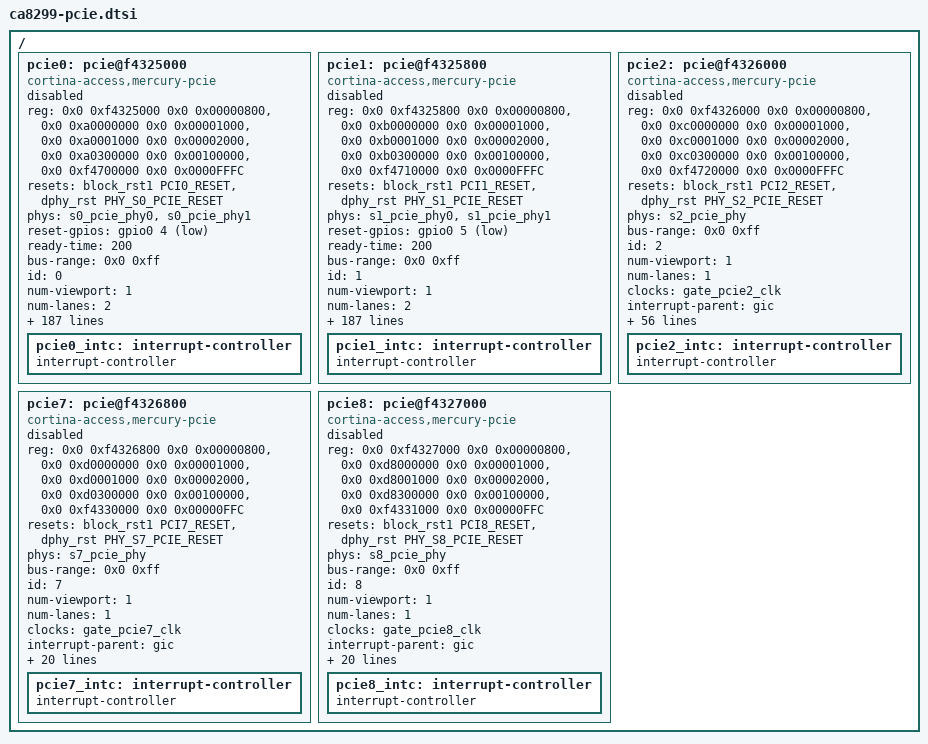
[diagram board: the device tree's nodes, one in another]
// SPDX-License-Identifier: GPL-2.0
/*
 * Copyright (C) 2024, Cortina Access Inc.
 *
 * ca8299-pcie.dtsi - Device Tree Include file for CA8299
 * pin controller.
 */
#include <dt-bindings/gpio/gpio.h>
/ {

/* Synopsis Designware PCIe interface */
	/* explained in Documentation/devicetree/bindings/pci/ca77xx-pcie.txt */
	//pcie0: pcie@f4325080 {
	pcie0: pcie@f4325000 {
		compatible = "cortina-access,mercury-pcie";
		reg = <0x0 0xf4325000 0x0 0x00000800>,
		      <0x0 0xa0000000 0x0 0x00001000>,
		      <0x0 0xa0001000 0x0 0x00002000>,
		      <0x0 0xa0300000 0x0 0x00100000>,
		      <0x0 0xf4700000 0x0 0x0000FFFC>;
		reg-names = "glbl_regs", "rc_dbi", "config", "iatu","serdes_phy";

		resets = <&block_rst1 PCI0_RESET>, <&dphy_rst PHY_S0_PCIE_RESET>;
		reset-names = "core_reset", "phy_reset";

		phys = <&s0_pcie_phy0>, <&s0_pcie_phy1>;
		phy-names = "pcie-phy0", "pcie-phy1";

		reset-gpios = <&gpio0 4 GPIO_ACTIVE_LOW>;
		ready-time = /bits/ 16 <200>;

		#address-cells = <3>;
		#size-cells = <2>;

		device_type = "pci";
		bus-range = <0x0 0xff>;
		ranges = <0x81000000 0 0          0 0xa0003000 0 0x00010000
			/* downstream I/O */
			/* 0xa0300000 - 0xa03fffff reserved for controller */
			0x82000000 0 0xa0400000 0 0xa0400000 0 0x0fc00000>;
			/* non-prefetchable memory */

		id = <0>;
		num-viewport = <1>;
		num-lanes = <2>;
		clocks = <&gate_pcie0_clk>;
		//iommus = <&pcie0_atu>;

		interrupt-parent = <&gic>;
		interrupts = <GIC_SPI IRQ_GLB_PCIE0_GIC0 IRQ_TYPE_LEVEL_HIGH>,
					/* controller interrupt */
					<GIC_SPI IRQ_GLB_PCIE0_GIC1 IRQ_TYPE_LEVEL_HIGH>,
					<GIC_SPI IRQ_GLB_PCIE0_GIC2 IRQ_TYPE_LEVEL_HIGH>,
					<GIC_SPI IRQ_GLB_PCIE0_GIC3 IRQ_TYPE_LEVEL_HIGH>;

		irq-affinity = <1>;  /*RTK wifi. Bound to CPU1. */

		status = "disabled";
		/* Serdes PHY parameters */
		serdes-cfg-verA = "revA v0.7 (2025.02.19)";
		serdes-cfg-dataA =
					<0x70B8 0x08f0>,
					<0x8180 0x40c1>,
					<0x9180 0x40c1>,
					<0xA180 0x40c1>,
					<0xB180 0x40c1>,
					<0x8580 0x40c1>,
					<0x9580 0x40c1>,
					<0xA580 0x40c1>,
					<0xB580 0x40c1>,
					<0x80C0 0xffd0>,
					<0x90C0 0xffd0>,
					<0xA0C0 0xffd0>,
					<0xB0C0 0xffd0>,
					<0x84C0 0xffd0>,
					<0x94C0 0xffd0>,
					<0xA4C0 0xffd0>,
					<0xB4C0 0xffd0>,
					<0x8090 0x0100>,
					<0x9090 0x0100>,
					<0xA090 0x0100>,
					<0xB090 0x0100>,
					<0x8490 0x0100>,
					<0x9490 0x0100>,
					<0xA490 0x0100>,
					<0xB490 0x0100>,
					<0x011C 0x2>,
					<0x051C 0x2>,
					<0x091C 0x2>,
					<0x0D1C 0x2>,
					<0x01DC 0x2>,
					<0x05DC 0x2>,
					<0x09DC 0x2>,
					<0x0DDC 0x2>,
					<0x0124 0x4001>,
					<0x0524 0x4001>,
					<0x0924 0x4001>,
					<0x0D24 0x4001>,
					<0x01E4 0x4001>,
					<0x05E4 0x4001>,
					<0x09E4 0x4001>,
					<0x0DE4 0x4001>,
					<0x012C 0x38>,
					<0x052C 0x38>,
					<0x092C 0x38>,
					<0x0D2C 0x38>,
					<0x01EC 0x38>,
					<0x05EC 0x38>,
					<0x09EC 0x38>,
					<0x0DEC 0x38>,
					<0x8028 0x3000>,
					<0x9028 0x2000>,
					<0xA028 0x2000>,
					<0xB028 0x2000>,
					<0x8428 0x3000>,
					<0x9428 0x2000>,
					<0xA428 0x2000>,
					<0xB428 0x2000>,
					<0x8130 0xFECF>,
					<0x9130 0xFECF>,
					<0xA130 0xFECF>,
					<0xB130 0xFECF>,
					<0x8530 0xFECF>,
					<0x9530 0xFECF>,
					<0xA530 0xFECF>,
					<0xB530 0xFECF>,
					<0x80D0 0xaff0>,
					<0x90D0 0xaff0>,
					<0xA0D0 0xaff0>,
					<0xB0D0 0x9840>,
					<0x84D0 0xaff0>,
					<0x94D0 0xaff0>,
					<0xA4D0 0xaff0>,
					<0xB4D0 0x9840>,
					<0x8150 0x79e>,
					<0x9150 0x79e>,
					<0xA150 0x79e>,
					<0xB150 0x79e>,
					<0x8550 0x79e>,
					<0x9550 0x79e>,
					<0xA550 0x79e>,
					<0xB550 0x79e>,
					<0x81C8 0x8038>,
					<0x91C8 0x8038>,
					<0xA1C8 0x8038>,
					<0xB1C8 0x8038>,
					<0x85C8 0x8038>,
					<0x95C8 0x8038>,
					<0xA5C8 0x8038>,
					<0xB5C8 0x8038>,
					<0x80A8 0x3f20>,
					<0x90A8 0x3f20>,
					<0xA0A8 0x3f20>,
					<0xB0A8 0x3f20>,
					<0x84A8 0x3f20>,
					<0x94A8 0x3f20>,
					<0xA4A8 0x3f20>,
					<0xB4A8 0x3f20>,
					<0x8248 0x6002>,
					<0x9248 0x6002>,
					<0xA248 0x2002>,
					<0xB248 0x2002>,
					<0x8648 0x6002>,
					<0x9648 0x6002>,
					<0xA648 0x2002>,
					<0xB648 0x2002>,
					<0x8250 0x8008>,
					<0x9250 0x8008>,
					<0xA250 0x8008>,
					<0xB250 0x8008>,
					<0x8650 0x8008>,
					<0x9650 0x8008>,
					<0xA650 0x8008>,
					<0xB650 0x8008>,
					<0x8268 0xc49>,
					<0x9268 0xc49>,
					<0xA268 0xe49>,
					<0xB268 0xe49>,
					<0x8668 0xc49>,
					<0x9668 0xc49>,
					<0xA668 0xe49>,
					<0xB668 0xe49>,
					<0x8110 0x7800>,
					<0x9110 0x7800>,
					<0xA110 0x7800>,
					<0xB110 0x7800>,
					<0x8510 0x7800>,
					<0x9510 0x7800>,
					<0xA510 0x7800>,
					<0xB510 0x7800>,
					<0x8118 0x7800>,
					<0x9118 0x7800>,
					<0xA118 0x7800>,
					<0xB118 0x7800>,
					<0x8518 0x7800>,
					<0x9518 0x7800>,
					<0xA518 0x7800>,
					<0xB518 0x7800>,
					<0x8120 0x320>,
					<0x9120 0x320>,
					<0xA120 0x320>,
					<0xB120 0x320>,
					<0x8520 0x320>,
					<0x9520 0x320>,
					<0xA520 0x320>,
					<0xB520 0x320>,
					<0x8128 0x320>,
					<0x9128 0x320>,
					<0xA128 0x320>,
					<0xB128 0x320>,
					<0x8528 0x320>,
					<0x9528 0x320>,
					<0xA528 0x320>,
					<0xB528 0x320>,
					<0x8148 0x80A6>,
					<0x9148 0x80A6>,
					<0xA148 0x80A6>,
					<0xB148 0x80A6>,
					<0x8548 0x80A6>,
					<0x9548 0x80A6>,
					<0xA548 0x80A6>,
					<0xB548 0x80A6>,
					<0x8140 0x0000>,
					<0x9140 0x0000>,
					<0xA140 0x0000>,
					<0xB140 0x3980>,
					<0x8540 0x0000>,
					<0x9540 0x0000>,
					<0xA540 0x0000>,
					<0xB540 0x3980>,
					<0x8178 0x0000>,
					<0x9178 0x0000>,
					<0xA178 0x0000>,
					<0xB178 0x0000>,
					<0x8578 0x0000>,
					<0x9578 0x0000>,
					<0xA578 0x0000>,
					<0xB578 0x0000>,
					<0x8108 0x0010>,
					<0x9108 0x0010>,
					<0xA108 0x0010>,
					<0xB108 0x0010>,
					<0x8508 0x0010>,
					<0x9508 0x0010>,
					<0xA508 0x0010>,
					<0xB508 0x0010>,
					<0x8160 0x2>,
					<0x9160 0x2>,
					<0xA160 0x2>,
					<0xB160 0x2>,
					<0x8560 0x2>,
					<0x9560 0x2>,
					<0xA560 0x2>,
					<0xB560 0x2>,
					<0x8168 0x0>,
					<0x9168 0x0>,
					<0xA168 0x0>,
					<0xB168 0x0>,
					<0x8568 0x0>,
					<0x9568 0x0>,
					<0xA568 0x0>,
					<0xB568 0x0>,
					<0x81E0 0x00ff>,
					<0x91E0 0x00ff>,
					<0xA1E0 0x00ff>,
					<0xB1E0 0x00ff>,
					<0x85E0 0x00ff>,
					<0x95E0 0x00ff>,
					<0xA5E0 0x00ff>,
					<0xB5E0 0x00ff>,
					<0x81F0 0x00ff>,
					<0x91F0 0x00ff>,
					<0xA1F0 0x00ff>,
					<0xB1F0 0x00ff>,
					<0x85F0 0x00ff>,
					<0x95F0 0x00ff>,
					<0xA5F0 0x00ff>,
					<0xB5F0 0x00ff>,
					<0x8260 0x2000>,
					<0x9260 0x2000>,
					<0xA260 0x2000>,
					<0xB260 0x2000>,
					<0x8660 0x2000>,
					<0x9660 0x2000>,
					<0xA660 0x2000>,
					<0xB660 0x2000>,
					<0x8220 0x64>,
					<0x9220 0x64>,
					<0xA220 0x64>,
					<0xB220 0x64>,
					<0x8620 0x64>,
					<0x9620 0x64>,
					<0xA620 0x64>,
					<0xB620 0x64>,
					<0x8230 0x2700>,
					<0x9230 0x2700>,
					<0xA230 0x3E70>,
					<0xB230 0x3E70>,
					<0x8630 0x2700>,
					<0x9630 0x2700>,
					<0xA630 0x3E70>,
					<0xB630 0x3E70>,
					<0x8228 0x2700>,
					<0x9228 0x2700>,
					<0xA228 0x3E70>,
					<0xB228 0x3E70>,
					<0x8628 0x2700>,
					<0x9628 0x2700>,
					<0xA628 0x3E70>,
					<0xB628 0x3E70>,
					<0xC000 0x0fff>,
					<0xD000 0x0fff>,
					<0xE000 0x0fff>,
					<0xF000 0x0fff>,
					<0x8270 0x6780>,
					<0x9270 0x6780>,
					<0xA270 0x6780>,
					<0xB270 0x6780>,
					<0x8670 0x6780>,
					<0x9670 0x6780>,
					<0xA670 0x6780>,
					<0xB670 0x6780>,
					<0x81B8 0x6000>,
					<0x91B8 0x6000>,
					<0xA1B8 0x6000>,
					<0xB1B8 0x6000>,
					<0x85B8 0x6000>,
					<0x95B8 0x6000>,
					<0xA5B8 0x6000>,
					<0xB5B8 0x6000>,
					<0x0058 0xc970>,
					<0x0458 0xc970>,
					<0x0858 0xc970>,
					<0x0C58 0xc970>,
					<0x0044 0xc10d>,
					<0x0444 0xc10d>,
					<0x0844 0xc10d>,
					<0x0C44 0xc10c>,
					<0x0068 0xd2f0>,
					<0x0468 0xd2f0>,
					<0x0868 0x52f0>,
					<0x0C68 0x52f0>,
					<0x00C8 0x5c0f>,
					<0x04C8 0x6c0f>,
					<0x08C8 0x7c0f>,
					<0x0CC8 0x7c0f>,
					<0x0188 0x5c0f>,
					<0x0588 0x6c0f>,
					<0x0988 0x7c0f>,
					<0x0D88 0x7c0f>,
					<0x00DC 0x0240>,
					<0x04DC 0x0240>,
					<0x08DC 0x0240>,
					<0x0CDC 0x0240>,
					<0x019C 0x0240>,
					<0x059C 0x0240>,
					<0x099C 0x0240>,
					<0x0D9C 0x0240>,
					<0x00C0 0x0600>,
					<0x04C0 0x0600>,
					<0x08C0 0x0e00>,
					<0x0CC0 0x0e00>,
					<0x0180 0x0600>,
					<0x0580 0x0600>,
					<0x0980 0x0e00>,
					<0x0D80 0x0e00>,
					<0xC118 0x2b>,
					<0xD118 0x2b>,
					<0xE118 0x2b>,
					<0xF118 0x2b>,
					<0x7218 0xf104>,
					<0x7258 0xf145>,
					<0x7260 0xe1c7>,
					<0x7280 0x9880>,
					<0x72C0 0xd880>,
					<0x016C 0x8044>,
					<0x056C 0x8044>,
					<0x096C 0x8044>,
					<0x0D6C 0x804c>,
					<0x022C 0x8044>,
					<0x062C 0x8044>,
					<0x0A2C 0x8044>,
					<0x0E2C 0x804c>,
					<0x0174 0x8e7c>,
					<0x0574 0x8e7c>,
					<0x0974 0x8e7c>,
					<0x0D74 0x8e7c>,
					<0x0234 0x8e7c>,
					<0x0634 0x8e7c>,
					<0x0A34 0x8e7c>,
					<0x0E34 0x8e7c>,
					<0x015C 0x8000>,
					<0x055C 0x8000>,
					<0x095C 0x1000>,
					<0x0D5C 0x1000>,
					<0x021C 0x8000>,
					<0x061C 0x8000>,
					<0x0A1C 0x1000>,
					<0x0E1C 0x1000>,
					<0x0104 0x1e4>,
					<0x0504 0x1e4>,
					<0x0904 0x0a4>,
					<0x0D04 0x0a4>,
					<0x01C4 0x1e4>,
					<0x05C4 0x1e4>,
					<0x09C4 0x0a4>,
					<0x0DC4 0x0a4>,
					<0x0138 0x0744>,
					<0x0538 0x0044>,
					<0x0938 0x0043>,
					<0x0D38 0x0043>,
					<0x01F8 0x0744>,
					<0x05F8 0x0044>,
					<0x09F8 0x0043>,
					<0x0DF8 0x0043>,
					<0x0170 0x8864>,
					<0x0570 0x8864>,
					<0x0970 0x8864>,
					<0x0D70 0x8864>,
					<0x0230 0x8864>,
					<0x0630 0x8864>,
					<0x0A30 0x8864>,
					<0x0E30 0x8864>,
					<0x0164 0x5680>,
					<0x0564 0x5680>,
					<0x0964 0x5a82>,
					<0x0D64 0x5a82>,
					<0x0224 0x5680>,
					<0x0624 0x5680>,
					<0x0A24 0x5a82>,
					<0x0E24 0x5a82>,
					<0x80B0 0x000d>,
					<0x90B0 0x000d>,
					<0xA0B0 0x000d>,
					<0xB0B0 0x000d>,
					<0x84B0 0x000d>,
					<0x94B0 0x000d>,
					<0xA4B0 0x000d>,
					<0xB4B0 0x000d>,
					<0x8258 0x1ff>,
					<0x9258 0x1ff>,
					<0xA258 0x1ff>,
					<0xB258 0x1ff>,
					<0x8658 0x1ff>,
					<0x9658 0x1ff>,
					<0xA658 0x1ff>,
					<0xB658 0x1ff>,
					<0x8210 0x3>,
					<0x9210 0x3>,
					<0xA210 0x3>,
					<0xB210 0x3>,
					<0x8610 0x3>,
					<0x9610 0x3>,
					<0xA610 0x3>,
					<0xB610 0x3>,
					<0x0108 0x17>,
					<0x0508 0x16>,
					<0x0908 0x14>,
					<0x0D08 0x10>,
					<0x01C8 0x17>,
					<0x05C8 0x16>,
					<0x09C8 0x14>,
					<0x0DC8 0x10>,
					<0x80A0 0x11e0>,
					<0x90A0 0x11e0>,
					<0xA0A0 0x11e0>,
					<0xB0A0 0x11e0>,
					<0x84A0 0x11e0>,
					<0x94A0 0x11e0>,
					<0xA4A0 0x11e0>,
					<0xB4A0 0x11e0>,
					<0x8030 0x200>,
					<0x9030 0x200>,
					<0xA030 0x200>,
					<0xB030 0x200>,
					<0x8430 0x200>,
					<0x9430 0x200>,
					<0xA430 0x200>,
					<0xB430 0x200>,
					<0x0100 0x67c3>,
					<0x0500 0x67c3>,
					<0x0900 0x67c3>,
					<0x0D00 0x66c3>,
					<0x01C0 0x67c3>,
					<0x05C0 0x67c3>,
					<0x09C0 0x67c3>,
					<0x0DC0 0x66c3>,
					<0x0144 0xe0c>,
					<0x0544 0xe0c>,
					<0x0944 0x60c>,
					<0x0D44 0x40c>,
					<0x0204 0xe0c>,
					<0x0604 0xe0c>,
					<0x0A04 0x60c>,
					<0x0E04 0x40c>,
					<0x0148 0xa63>,
					<0x0548 0xa63>,
					<0x0948 0xa63>,
					<0x0D48 0xa63>,
					<0x0208 0xa63>,
					<0x0608 0xa63>,
					<0x0A08 0xa63>,
					<0x0E08 0xa63>,
					<0x0168 0x101A>,
					<0x0568 0x101A>,
					<0x0968 0x101A>,
					<0x0D68 0x101A>,
					<0x0228 0x101A>,
					<0x0628 0x101A>,
					<0x0A28 0x101A>,
					<0x0E28 0x101A>,
					<0x0158 0x4200>,
					<0x0558 0x4200>,
					<0x0958 0x4200>,
					<0x0D58 0x4200>,
					<0x0218 0x4200>,
					<0x0618 0x4200>,
					<0x0A18 0x4200>,
					<0x0E18 0x4200>,
					<0x81D0 0xffff>,
					<0x91D0 0xffff>,
					<0xA1D0 0xffff>,
					<0xB1D0 0xffff>,
					<0x85D0 0xffff>,
					<0x95D0 0xffff>,
					<0xA5D0 0xffff>,
					<0xB5D0 0xffff>,
					<0x8098 0x108>,
					<0x9098 0x108>,
					<0xA098 0x108>,
					<0xB098 0x108>,
					<0x8498 0x108>,
					<0x9498 0x108>,
					<0xA498 0x108>,
					<0xB498 0x108>,
					<0x8068 0x426c>,
					<0x9068 0x426c>,
					<0xA068 0x426c>,
					<0xB068 0xc26c>,
					<0x8468 0x426c>,
					<0x9468 0x426c>,
					<0xA468 0x426c>,
					<0xB468 0xc26c>,
					<0x8008 0x0000>,
					<0x9008 0x0000>,
					<0xA008 0x0000>,
					<0xB008 0x60>,
					<0x8408 0x0000>,
					<0x9408 0x0000>,
					<0xA408 0x0000>,
					<0xB408 0x60>;

		mac_pset_fs = <42>;
		mac_pset_lf = <14>;
		mac_preset_cfg = /*p0 - p10, Pre, Main, Post*/
					<0 31 11>,
					<0 35 7>,
					<0 34 8>,
					<0 37 5>,
					<0 42 0>,
					<4 38 0>,
					<5 37 0>,
					<4 30 8>,
					<5 32 5>,
					<7 35 0>,
					<0 28 14>;

		ephy_cnt = <3>;
		ephy_addr = /bits/ 16
						<0x1c62 0x1c60 0x1c60>;

		tx_data_size = <147>;
		tx_matrix_data = /bits/ 16
					<0x0 0x3C0 0x0
					0x821 0x3C1 0x1
					0x1042 0x3C2 0x2
					0x1863 0x3C3 0x3
					0x2084 0x3C4 0x4
					0x28A6 0x3C5 0x5
					0x30C7 0x3C6 0x6
					0x40E8 0x3C7 0x7
					0x4909 0x3C8 0x8
					0x5129 0x3C9 0x9
					0x5949 0x3CA 0xA
					0x6169 0x3CB 0xB
					0x6989 0x3CC 0xC
					0x71A9 0x3CD 0xD
					0x71C9 0x3CE 0xE
					0x79E9 0x3CF 0xF
					0x7A09 0x3D0 0x10
					0x7A49 0x3D1 0x11
					0x7A69 0x3D2 0x12
					0x7A89 0x3D3 0x13
					0x7AA9 0x3D4 0x14
					0x7AE9 0x3D5 0x15
					0x7B09 0x3D6 0x16
					0x7B29 0x3D7 0x17
					0x7B69 0x3D8 0x18
					0x7B89 0x3D9 0x19
					0x7BC9 0x3DA 0x1A
					0x7C09 0x3DB 0x1B
					0x7C49 0x3DC 0x1C
					0x7C89 0x3DD 0x1D
					0x7CC9 0x3DE 0x1E
					0x7D09 0x3DF 0x1F
					0x7D69 0x3E0 0x20
					0x7DC9 0x3E1 0x21
					0x7E29 0x3E2 0x22
					0x7EA9 0x3E3 0x23
					0x7F69 0x3E4 0x24
					0x7FE9 0x3E5 0x25
					0x7FE9 0x3E6 0x26
					0x7FE9 0x3E7 0x27
					0x7FE9 0x3E8 0x28
					0x7FE9 0x3E9 0x29
					0x7FE9 0x3EA 0x2A
					0x7FE9 0x3EB 0x2B
					0x7FE9 0x3EC 0x2C
					0x7FE9 0x3ED 0x2D
					0x7FE9 0x3EE 0x2E
					0x7FE9 0x3EF 0x2F
					0x7FE9 0x3F0 0x30>;

		#interrupt-cells = <1>;
		interrupt-map-mask = <0 0 0 7>;
//		interrupt-map-mask = <0xffffffff 0x0>;
		interrupt-map = <0 0 0 1 &pcie0_intc 1>, /* INT A */
				<0 0 0 2 &pcie0_intc 2>, /* INT B */
				<0 0 0 3 &pcie0_intc 3>, /* INT C */
				<0 0 0 4 &pcie0_intc 4>; /* INT D */
		pcie0_intc: interrupt-controller {
			interrupt-controller;
			#address-cells = <0>;
			#interrupt-cells = <1>;
		};
	};
	pcie1: pcie@f4325800 {
		compatible = "cortina-access,mercury-pcie";
		reg = <0x0 0xf4325800 0x0 0x00000800>,
		      <0x0 0xb0000000 0x0 0x00001000>,
		      <0x0 0xb0001000 0x0 0x00002000>,
		      <0x0 0xb0300000 0x0 0x00100000>,
		      <0x0 0xf4710000 0x0 0x0000FFFC>;
		reg-names = "glbl_regs", "rc_dbi", "config", "iatu","serdes_phy";

		resets = <&block_rst1 PCI1_RESET>, <&dphy_rst PHY_S1_PCIE_RESET>;
		reset-names = "core_reset", "phy_reset";

		phys = <&s1_pcie_phy0>, <&s1_pcie_phy1>;
		phy-names = "pcie-phy0", "pcie-phy1";

		reset-gpios = <&gpio0 5 GPIO_ACTIVE_LOW>;
		ready-time = /bits/ 16 <200>;

		#address-cells = <3>;
		#size-cells = <2>;

		device_type = "pci";
		bus-range = <0x0 0xff>;
		ranges = <0x81000000 0 0          0 0xb0003000 0 0x00010000
			/* downstream I/O */
			/* 0xb0300000 - 0xb03fffff reserved for controller */
			0x82000000 0 0xb0400000 0 0xb0400000 0 0x0fc00000>;
			/* non-prefetchable memory */

		id = <1>;
		num-viewport = <1>;
		num-lanes = <2>;
		clocks = <&gate_pcie1_clk>;
		//iommus = <&pcie1_atu>;

		interrupt-parent = <&gic>;
		interrupts = <GIC_SPI IRQ_GLB_PCIE1_GIC0 IRQ_TYPE_LEVEL_HIGH>,
					/* controller interrupt */
					<GIC_SPI IRQ_GLB_PCIE1_GIC1 IRQ_TYPE_LEVEL_HIGH>,
					<GIC_SPI IRQ_GLB_PCIE1_GIC2 IRQ_TYPE_LEVEL_HIGH>,
					<GIC_SPI IRQ_GLB_PCIE1_GIC3 IRQ_TYPE_LEVEL_HIGH>;

		irq-affinity = <1>;  /*RTK wifi. Bound to CPU1. */

		status = "disabled";
		/* Serdes PHY parameters */
		serdes-cfg-verA = "revA v0.7 (2025.02.19)";
		serdes-cfg-dataA =
					<0x70B8 0x08f0>,
					<0x8180 0x40c1>,
					<0x9180 0x40c1>,
					<0xA180 0x40c1>,
					<0xB180 0x40c1>,
					<0x8580 0x40c1>,
					<0x9580 0x40c1>,
					<0xA580 0x40c1>,
					<0xB580 0x40c1>,
					<0x80C0 0xffd0>,
					<0x90C0 0xffd0>,
					<0xA0C0 0xffd0>,
					<0xB0C0 0xffd0>,
					<0x84C0 0xffd0>,
					<0x94C0 0xffd0>,
					<0xA4C0 0xffd0>,
					<0xB4C0 0xffd0>,
					<0x8090 0x0100>,
					<0x9090 0x0100>,
					<0xA090 0x0100>,
					<0xB090 0x0100>,
					<0x8490 0x0100>,
					<0x9490 0x0100>,
					<0xA490 0x0100>,
					<0xB490 0x0100>,
					<0x011C 0x2>,
					<0x051C 0x2>,
					<0x091C 0x2>,
					<0x0D1C 0x2>,
					<0x01DC 0x2>,
					<0x05DC 0x2>,
					<0x09DC 0x2>,
					<0x0DDC 0x2>,
					<0x0124 0x4001>,
					<0x0524 0x4001>,
					<0x0924 0x4001>,
					<0x0D24 0x4001>,
					<0x01E4 0x4001>,
					<0x05E4 0x4001>,
					<0x09E4 0x4001>,
					<0x0DE4 0x4001>,
					<0x012C 0x38>,
					<0x052C 0x38>,
					<0x092C 0x38>,
					<0x0D2C 0x38>,
					<0x01EC 0x38>,
					<0x05EC 0x38>,
					<0x09EC 0x38>,
					<0x0DEC 0x38>,
					<0x8028 0x3000>,
					<0x9028 0x2000>,
					<0xA028 0x2000>,
					<0xB028 0x2000>,
					<0x8428 0x3000>,
					<0x9428 0x2000>,
					<0xA428 0x2000>,
					<0xB428 0x2000>,
					<0x8130 0xFECF>,
					<0x9130 0xFECF>,
					<0xA130 0xFECF>,
					<0xB130 0xFECF>,
					<0x8530 0xFECF>,
					<0x9530 0xFECF>,
					<0xA530 0xFECF>,
					<0xB530 0xFECF>,
					<0x80D0 0xaff0>,
					<0x90D0 0xaff0>,
					<0xA0D0 0xaff0>,
					<0xB0D0 0x9840>,
					<0x84D0 0xaff0>,
					<0x94D0 0xaff0>,
					<0xA4D0 0xaff0>,
					<0xB4D0 0x9840>,
					<0x8150 0x79e>,
					<0x9150 0x79e>,
					<0xA150 0x79e>,
					<0xB150 0x79e>,
					<0x8550 0x79e>,
					<0x9550 0x79e>,
					<0xA550 0x79e>,
					<0xB550 0x79e>,
					<0x81C8 0x8038>,
					<0x91C8 0x8038>,
					<0xA1C8 0x8038>,
					<0xB1C8 0x8038>,
					<0x85C8 0x8038>,
					<0x95C8 0x8038>,
					<0xA5C8 0x8038>,
					<0xB5C8 0x8038>,
					<0x80A8 0x3f20>,
					<0x90A8 0x3f20>,
					<0xA0A8 0x3f20>,
					<0xB0A8 0x3f20>,
					<0x84A8 0x3f20>,
					<0x94A8 0x3f20>,
					<0xA4A8 0x3f20>,
					<0xB4A8 0x3f20>,
					<0x8248 0x6002>,
					<0x9248 0x6002>,
					<0xA248 0x2002>,
					<0xB248 0x2002>,
					<0x8648 0x6002>,
					<0x9648 0x6002>,
					<0xA648 0x2002>,
					<0xB648 0x2002>,
					<0x8250 0x8008>,
					<0x9250 0x8008>,
					<0xA250 0x8008>,
					<0xB250 0x8008>,
					<0x8650 0x8008>,
					<0x9650 0x8008>,
					<0xA650 0x8008>,
					<0xB650 0x8008>,
					<0x8268 0xc49>,
					<0x9268 0xc49>,
					<0xA268 0xe49>,
					<0xB268 0xe49>,
					<0x8668 0xc49>,
					<0x9668 0xc49>,
					<0xA668 0xe49>,
					<0xB668 0xe49>,
					<0x8110 0x7800>,
					<0x9110 0x7800>,
					<0xA110 0x7800>,
					<0xB110 0x7800>,
					<0x8510 0x7800>,
					<0x9510 0x7800>,
					<0xA510 0x7800>,
					<0xB510 0x7800>,
					<0x8118 0x7800>,
					<0x9118 0x7800>,
					<0xA118 0x7800>,
					<0xB118 0x7800>,
					<0x8518 0x7800>,
					<0x9518 0x7800>,
					<0xA518 0x7800>,
					<0xB518 0x7800>,
					<0x8120 0x320>,
					<0x9120 0x320>,
					<0xA120 0x320>,
					<0xB120 0x320>,
					<0x8520 0x320>,
					<0x9520 0x320>,
					<0xA520 0x320>,
					<0xB520 0x320>,
					<0x8128 0x320>,
					<0x9128 0x320>,
					<0xA128 0x320>,
					<0xB128 0x320>,
					<0x8528 0x320>,
					<0x9528 0x320>,
					<0xA528 0x320>,
					<0xB528 0x320>,
					<0x8148 0x80A6>,
					<0x9148 0x80A6>,
					<0xA148 0x80A6>,
					<0xB148 0x80A6>,
					<0x8548 0x80A6>,
					<0x9548 0x80A6>,
					<0xA548 0x80A6>,
					<0xB548 0x80A6>,
					<0x8140 0x0000>,
					<0x9140 0x0000>,
					<0xA140 0x0000>,
					<0xB140 0x3980>,
					<0x8540 0x0000>,
					<0x9540 0x0000>,
					<0xA540 0x0000>,
					<0xB540 0x3980>,
					<0x8178 0x0000>,
					<0x9178 0x0000>,
					<0xA178 0x0000>,
					<0xB178 0x0000>,
					<0x8578 0x0000>,
					<0x9578 0x0000>,
					<0xA578 0x0000>,
					<0xB578 0x0000>,
					<0x8108 0x0010>,
					<0x9108 0x0010>,
					<0xA108 0x0010>,
					<0xB108 0x0010>,
					<0x8508 0x0010>,
					<0x9508 0x0010>,
					<0xA508 0x0010>,
					<0xB508 0x0010>,
					<0x8160 0x2>,
					<0x9160 0x2>,
					<0xA160 0x2>,
					<0xB160 0x2>,
					<0x8560 0x2>,
					<0x9560 0x2>,
					<0xA560 0x2>,
					<0xB560 0x2>,
					<0x8168 0x0>,
					<0x9168 0x0>,
					<0xA168 0x0>,
					<0xB168 0x0>,
					<0x8568 0x0>,
					<0x9568 0x0>,
					<0xA568 0x0>,
					<0xB568 0x0>,
					<0x81E0 0x00ff>,
					<0x91E0 0x00ff>,
					<0xA1E0 0x00ff>,
					<0xB1E0 0x00ff>,
					<0x85E0 0x00ff>,
					<0x95E0 0x00ff>,
					<0xA5E0 0x00ff>,
					<0xB5E0 0x00ff>,
					<0x81F0 0x00ff>,
					<0x91F0 0x00ff>,
					<0xA1F0 0x00ff>,
					<0xB1F0 0x00ff>,
					<0x85F0 0x00ff>,
					<0x95F0 0x00ff>,
					<0xA5F0 0x00ff>,
					<0xB5F0 0x00ff>,
					<0x8260 0x2000>,
					<0x9260 0x2000>,
					<0xA260 0x2000>,
					<0xB260 0x2000>,
					<0x8660 0x2000>,
					<0x9660 0x2000>,
					<0xA660 0x2000>,
					<0xB660 0x2000>,
					<0x8220 0x64>,
					<0x9220 0x64>,
					<0xA220 0x64>,
					<0xB220 0x64>,
					<0x8620 0x64>,
					<0x9620 0x64>,
					<0xA620 0x64>,
					<0xB620 0x64>,
					<0x8230 0x2700>,
					<0x9230 0x2700>,
					<0xA230 0x3E70>,
					<0xB230 0x3E70>,
					<0x8630 0x2700>,
					<0x9630 0x2700>,
					<0xA630 0x3E70>,
					<0xB630 0x3E70>,
					<0x8228 0x2700>,
					<0x9228 0x2700>,
					<0xA228 0x3E70>,
					<0xB228 0x3E70>,
					<0x8628 0x2700>,
					<0x9628 0x2700>,
					<0xA628 0x3E70>,
					<0xB628 0x3E70>,
					<0xC000 0x0fff>,
					<0xD000 0x0fff>,
					<0xE000 0x0fff>,
					<0xF000 0x0fff>,
					<0x8270 0x6780>,
					<0x9270 0x6780>,
					<0xA270 0x6780>,
					<0xB270 0x6780>,
					<0x8670 0x6780>,
					<0x9670 0x6780>,
					<0xA670 0x6780>,
					<0xB670 0x6780>,
					<0x81B8 0x6000>,
					<0x91B8 0x6000>,
					<0xA1B8 0x6000>,
					<0xB1B8 0x6000>,
					<0x85B8 0x6000>,
					<0x95B8 0x6000>,
					<0xA5B8 0x6000>,
					<0xB5B8 0x6000>,
					<0x0058 0xc970>,
					<0x0458 0xc970>,
					<0x0858 0xc970>,
					<0x0C58 0xc970>,
					<0x0044 0xc10d>,
					<0x0444 0xc10d>,
					<0x0844 0xc10d>,
					<0x0C44 0xc10c>,
					<0x0068 0xd2f0>,
					<0x0468 0xd2f0>,
					<0x0868 0x52f0>,
					<0x0C68 0x52f0>,
					<0x00C8 0x5c0f>,
					<0x04C8 0x6c0f>,
					<0x08C8 0x7c0f>,
					<0x0CC8 0x7c0f>,
					<0x0188 0x5c0f>,
					<0x0588 0x6c0f>,
					<0x0988 0x7c0f>,
					<0x0D88 0x7c0f>,
					<0x00DC 0x0240>,
					<0x04DC 0x0240>,
					<0x08DC 0x0240>,
					<0x0CDC 0x0240>,
					<0x019C 0x0240>,
					<0x059C 0x0240>,
					<0x099C 0x0240>,
					<0x0D9C 0x0240>,
					<0x00C0 0x0600>,
					<0x04C0 0x0600>,
					<0x08C0 0x0e00>,
					<0x0CC0 0x0e00>,
					<0x0180 0x0600>,
					<0x0580 0x0600>,
					<0x0980 0x0e00>,
					<0x0D80 0x0e00>,
					<0xC118 0x2b>,
					<0xD118 0x2b>,
					<0xE118 0x2b>,
					<0xF118 0x2b>,
					<0x7218 0xf104>,
					<0x7258 0xf145>,
					<0x7260 0xe1c7>,
					<0x7280 0x9880>,
					<0x72C0 0xd880>,
					<0x016C 0x8044>,
					<0x056C 0x8044>,
					<0x096C 0x8044>,
					<0x0D6C 0x804c>,
					<0x022C 0x8044>,
					<0x062C 0x8044>,
					<0x0A2C 0x8044>,
					<0x0E2C 0x804c>,
					<0x0174 0x8e7c>,
					<0x0574 0x8e7c>,
					<0x0974 0x8e7c>,
					<0x0D74 0x8e7c>,
					<0x0234 0x8e7c>,
					<0x0634 0x8e7c>,
					<0x0A34 0x8e7c>,
					<0x0E34 0x8e7c>,
					<0x015C 0x8000>,
					<0x055C 0x8000>,
					<0x095C 0x1000>,
					<0x0D5C 0x1000>,
					<0x021C 0x8000>,
					<0x061C 0x8000>,
					<0x0A1C 0x1000>,
					<0x0E1C 0x1000>,
					<0x0104 0x1e4>,
					<0x0504 0x1e4>,
					<0x0904 0x0a4>,
					<0x0D04 0x0a4>,
					<0x01C4 0x1e4>,
					<0x05C4 0x1e4>,
					<0x09C4 0x0a4>,
					<0x0DC4 0x0a4>,
					<0x0138 0x0744>,
					<0x0538 0x0044>,
					<0x0938 0x0043>,
					<0x0D38 0x0043>,
					<0x01F8 0x0744>,
					<0x05F8 0x0044>,
					<0x09F8 0x0043>,
					<0x0DF8 0x0043>,
					<0x0170 0x8864>,
					<0x0570 0x8864>,
					<0x0970 0x8864>,
					<0x0D70 0x8864>,
					<0x0230 0x8864>,
					<0x0630 0x8864>,
					<0x0A30 0x8864>,
					<0x0E30 0x8864>,
					<0x0164 0x5680>,
					<0x0564 0x5680>,
					<0x0964 0x5a82>,
					<0x0D64 0x5a82>,
					<0x0224 0x5680>,
					<0x0624 0x5680>,
					<0x0A24 0x5a82>,
					<0x0E24 0x5a82>,
					<0x80B0 0x000d>,
					<0x90B0 0x000d>,
					<0xA0B0 0x000d>,
					<0xB0B0 0x000d>,
					<0x84B0 0x000d>,
					<0x94B0 0x000d>,
					<0xA4B0 0x000d>,
					<0xB4B0 0x000d>,
					<0x8258 0x1ff>,
					<0x9258 0x1ff>,
					<0xA258 0x1ff>,
					<0xB258 0x1ff>,
					<0x8658 0x1ff>,
					<0x9658 0x1ff>,
					<0xA658 0x1ff>,
					<0xB658 0x1ff>,
					<0x8210 0x3>,
					<0x9210 0x3>,
					<0xA210 0x3>,
					<0xB210 0x3>,
					<0x8610 0x3>,
					<0x9610 0x3>,
					<0xA610 0x3>,
					<0xB610 0x3>,
					<0x0108 0x17>,
					<0x0508 0x16>,
					<0x0908 0x14>,
					<0x0D08 0x10>,
					<0x01C8 0x17>,
					<0x05C8 0x16>,
					<0x09C8 0x14>,
					<0x0DC8 0x10>,
					<0x80A0 0x11e0>,
					<0x90A0 0x11e0>,
					<0xA0A0 0x11e0>,
					<0xB0A0 0x11e0>,
					<0x84A0 0x11e0>,
					<0x94A0 0x11e0>,
					<0xA4A0 0x11e0>,
					<0xB4A0 0x11e0>,
					<0x8030 0x200>,
					<0x9030 0x200>,
					<0xA030 0x200>,
					<0xB030 0x200>,
					<0x8430 0x200>,
					<0x9430 0x200>,
					<0xA430 0x200>,
					<0xB430 0x200>,
					<0x0100 0x67c3>,
					<0x0500 0x67c3>,
					<0x0900 0x67c3>,
					<0x0D00 0x66c3>,
					<0x01C0 0x67c3>,
					<0x05C0 0x67c3>,
					<0x09C0 0x67c3>,
					<0x0DC0 0x66c3>,
					<0x0144 0xe0c>,
					<0x0544 0xe0c>,
					<0x0944 0x60c>,
					<0x0D44 0x40c>,
					<0x0204 0xe0c>,
					<0x0604 0xe0c>,
					<0x0A04 0x60c>,
					<0x0E04 0x40c>,
					<0x0148 0xa63>,
					<0x0548 0xa63>,
					<0x0948 0xa63>,
					<0x0D48 0xa63>,
					<0x0208 0xa63>,
					<0x0608 0xa63>,
					<0x0A08 0xa63>,
					<0x0E08 0xa63>,
					<0x0168 0x101A>,
					<0x0568 0x101A>,
					<0x0968 0x101A>,
					<0x0D68 0x101A>,
					<0x0228 0x101A>,
					<0x0628 0x101A>,
					<0x0A28 0x101A>,
					<0x0E28 0x101A>,
					<0x0158 0x4200>,
					<0x0558 0x4200>,
					<0x0958 0x4200>,
					<0x0D58 0x4200>,
					<0x0218 0x4200>,
					<0x0618 0x4200>,
					<0x0A18 0x4200>,
					<0x0E18 0x4200>,
					<0x81D0 0xffff>,
					<0x91D0 0xffff>,
					<0xA1D0 0xffff>,
					<0xB1D0 0xffff>,
					<0x85D0 0xffff>,
					<0x95D0 0xffff>,
					<0xA5D0 0xffff>,
					<0xB5D0 0xffff>,
					<0x8098 0x108>,
					<0x9098 0x108>,
					<0xA098 0x108>,
					<0xB098 0x108>,
					<0x8498 0x108>,
					<0x9498 0x108>,
					<0xA498 0x108>,
					<0xB498 0x108>,
					<0x8068 0x426c>,
					<0x9068 0x426c>,
					<0xA068 0x426c>,
					<0xB068 0xc26c>,
					<0x8468 0x426c>,
					<0x9468 0x426c>,
					<0xA468 0x426c>,
					<0xB468 0xc26c>,
					<0x8008 0x0000>,
					<0x9008 0x0000>,
					<0xA008 0x0000>,
					<0xB008 0x60>,
					<0x8408 0x0000>,
					<0x9408 0x0000>,
					<0xA408 0x0000>,
					<0xB408 0x60>;

		mac_pset_fs = <42>;
		mac_pset_lf = <14>;
		mac_preset_cfg = /*p0 - p10, Pre, Main, Post*/
				<0 31 11>,
				<0 35 7>,
				<0 34 8>,
				<0 37 5>,
				<0 42 0>,
				<4 38 0>,
				<5 37 0>,
				<4 30 8>,
				<5 32 5>,
				<7 35 0>,
				<0 28 14>;

		ephy_cnt = <3>;
		ephy_addr = /bits/ 16
						<0x1c62 0x1c60 0x1c60>;

		tx_data_size = <147>;
		tx_matrix_data = /bits/ 16
					<0x0 0x3C0 0x0
					0x821 0x3C1 0x1
					0x1042 0x3C2 0x2
					0x1863 0x3C3 0x3
					0x2084 0x3C4 0x4
					0x28A6 0x3C5 0x5
					0x30C7 0x3C6 0x6
					0x40E8 0x3C7 0x7
					0x4909 0x3C8 0x8
					0x5129 0x3C9 0x9
					0x5949 0x3CA 0xA
					0x6169 0x3CB 0xB
					0x6989 0x3CC 0xC
					0x71A9 0x3CD 0xD
					0x71C9 0x3CE 0xE
					0x79E9 0x3CF 0xF
					0x7A09 0x3D0 0x10
					0x7A49 0x3D1 0x11
					0x7A69 0x3D2 0x12
					0x7A89 0x3D3 0x13
					0x7AA9 0x3D4 0x14
					0x7AE9 0x3D5 0x15
					0x7B09 0x3D6 0x16
					0x7B29 0x3D7 0x17
					0x7B69 0x3D8 0x18
					0x7B89 0x3D9 0x19
					0x7BC9 0x3DA 0x1A
					0x7C09 0x3DB 0x1B
					0x7C49 0x3DC 0x1C
					0x7C89 0x3DD 0x1D
					0x7CC9 0x3DE 0x1E
					0x7D09 0x3DF 0x1F
					0x7D69 0x3E0 0x20
					0x7DC9 0x3E1 0x21
					0x7E29 0x3E2 0x22
					0x7EA9 0x3E3 0x23
					0x7F69 0x3E4 0x24
					0x7FE9 0x3E5 0x25
					0x7FE9 0x3E6 0x26
					0x7FE9 0x3E7 0x27
					0x7FE9 0x3E8 0x28
					0x7FE9 0x3E9 0x29
					0x7FE9 0x3EA 0x2A
					0x7FE9 0x3EB 0x2B
					0x7FE9 0x3EC 0x2C
					0x7FE9 0x3ED 0x2D
					0x7FE9 0x3EE 0x2E
					0x7FE9 0x3EF 0x2F
					0x7FE9 0x3F0 0x30>;

		#interrupt-cells = <1>;
		interrupt-map-mask = <0 0 0 7>;
		interrupt-map = <0 0 0 1 &pcie1_intc 1>, /* INT A */
				<0 0 0 2 &pcie1_intc 2>, /* INT B */
				<0 0 0 3 &pcie1_intc 3>, /* INT C */
				<0 0 0 4 &pcie1_intc 4>; /* INT D */
		pcie1_intc: interrupt-controller {
			interrupt-controller;
			#address-cells = <0>;
			#interrupt-cells = <1>;
		};
	};

	pcie2: pcie@f4326000 {
		compatible = "cortina-access,mercury-pcie";
		reg = <0x0 0xf4326000 0x0 0x00000800>,
		      <0x0 0xc0000000 0x0 0x00001000>,
		      <0x0 0xc0001000 0x0 0x00002000>,
		      <0x0 0xc0300000 0x0 0x00100000>,
		      <0x0 0xf4720000 0x0 0x0000FFFC>;
		reg-names = "glbl_regs", "rc_dbi", "config", "iatu","serdes_phy";

		resets = <&block_rst1 PCI2_RESET>, <&dphy_rst PHY_S2_PCIE_RESET>;
		reset-names = "core_reset", "phy_reset";

		phys = <&s2_pcie_phy>;
		phy-names = "pcie-phy";

		#address-cells = <3>;
		#size-cells = <2>;

		device_type = "pci";
		bus-range = <0x0 0xff>;
		ranges = <0x81000000 0 0          0 0xc0003000 0 0x00010000
			/* downstream I/O */
			/* 0xb0300000 - 0xb03fffff reserved for controller */
			0x82000000 0 0xc0400000 0 0xc0400000 0 0x0fc00000>;
			/* non-prefetchable memory */

		id = <2>;
		num-viewport = <1>;
		num-lanes = <1>;
		clocks = <&gate_pcie2_clk>;
		//iommus = <&pcie2_atu>;

		interrupt-parent = <&gic>;
		interrupts = <GIC_SPI IRQ_GLB_PCIE2_GIC0 IRQ_TYPE_LEVEL_HIGH>,
					/* controller interrupt */
					<GIC_SPI IRQ_GLB_PCIE2_GIC1 IRQ_TYPE_LEVEL_HIGH>,
					<GIC_SPI IRQ_GLB_PCIE2_GIC2 IRQ_TYPE_LEVEL_HIGH>,
					<GIC_SPI IRQ_GLB_PCIE2_GIC3 IRQ_TYPE_LEVEL_HIGH>;

		irq-affinity = <1>;  /*RTK wifi. Bound to CPU1. */

		status = "disabled";
		/* Serdes PHY parameters */
		serdes-cfg-verA = "revA v0.3 (2024.12.30)";
		serdes-cfg-dataA = /*S2*/
					<0x4480 0xc1fc>,
					<0x4540 0xc1fc>,
					<0x4488 0xe87f>,
					<0x4548 0xe87f>,
					<0x4608 0xe87f>,
					<0x44A8 0xe060>,
					<0x4568 0xe060>,
					<0x4628 0xe060>,
					<0x7CA0 0xc6>,
					<0x7CE0 0xc6>,
					<0x7D20 0x9e>,
					<0x7C88 0xc6>,
					<0x7CC8 0xc6>,
					<0x7D08 0x9e>,
					<0x7CA8 0x010>,
					<0x7CE8 0x010>,
					<0x7D28 0x018>,
					<0x7CB0 0x280>,
					<0x7CF0 0x280>,
					<0x7D30 0x300>,
					<0x7CB8 0x280>,
					<0x7CF8 0x280>,
					<0x7D38 0x300>,
					<0x6090 0x0280>,
					<0x6098 0x0280>,
					<0x7100 0x0001>,
					<0x0058 0x1821>,
					<0x0198 0x1821>,
					<0x02D8 0x1821>,
					<0x005C 0x0010>,
					<0x019C 0x0014>,
					<0x0070 0x0260>,
					<0x01B0 0x0260>,
					<0x02F0 0x0260>,
					<0x0104 0x0c45>,
					<0x0244 0x0c45>,
					<0x0108 0x11b>,
					<0x0248 0x11b>,
					<0x0388 0x11b>,
					<0x039C 0xf0f0>,
					<0x0130 0x31>,
					<0x0270 0x31>,
					<0x69E8 0x5000>,
					<0x4000 0x2>,
					<0x4018 0x0>,
					<0x4020 0x2034>,
					<0x0114 0x6fe2>,
					<0x0254 0x6fe2>,
					<0x0394 0x6fe0>,
					<0x012C 0x31b>,
					<0x026C 0x31b>,
					<0x03AC 0x31b>,
					<0x0050 0x13c>,
					<0x0190 0x13c>,
					<0x02D0 0x13c>,
					<0x004C 0x2006>,
					<0x018C 0x2007>,
					<0x02CC 0x2303>,
					<0x0000 0x1a0a>,
					<0x69A8 0xf100>,
					<0x69C8 0xe188>,
					<0x0384 0x45>,
					<0x65A8 0x4a5>,
					<0x65B8 0x31a>,
					<0x03B0 0x32>,
					<0x0070 0x0262>,
					<0x01B0 0x0262>,
					<0x02F0 0x0262>,
					<0x4410 0x700>,
					<0x44D0 0x380>,
					<0x4590 0x2c0>,
					<0x4408 0x700>,
					<0x44C8 0x380>,
					<0x4588 0x2c0>,
					<0x0024 0x4500>,
					<0x0164 0x4500>,
					<0x02A4 0x4500>,
					<0x6580 0x9880>,
					<0x000C 0xe0f3>,
					<0x014C 0xe0f3>,
					<0x028C 0xe0f3>,
					<0x4040 0xd900>,
					<0x4450 0x9c00>,
					<0x4510 0x0c00>,
					<0x4458 0x01f4>,
					<0x4518 0x01f4>,
					<0x45D8 0x01f4>,
					<0x6840 0x6fc0>,
					<0x68B8 0x0870>,
					<0x001C 0xEA3A>,
					<0x015C 0xEA3A>,
					<0x029C 0x6A7A>,
					<0x0018 0x8E8>,
					<0x0158 0x8E8>,
					<0x0298 0x8E0>,
					<0x0030 0xc580>,
					<0x0170 0xc580>,
					<0x02B0 0xc580>,
					<0x4600 0xFFFC>,
					<0x45E0 0x43ff>,
					<0x4548 0xe8ff>,
					<0x4608 0xe95f>,
					<0x6600 0x19>;

			mac_pset_fs = <40>;
			mac_pset_lf = <12>;
			mac_preset_cfg = /*p0 - p10, Pre, Main, Post*/
					<0 30 10>,
					<0 33 7>,
					<0 32 8>,
					<0 35 5>,
					<0 40 0>,
					<4 36 0>,
					<5 35 0>,
					<4 28 8>,
					<5 30 5>,
					<7 33 0>,
					<0 27 13>;

		ephy_cnt = <3>;
		ephy_addr = /bits/ 16
				<0x1a60 0x1a62 0x1a62>;
		tx_data_size = <123>;
		tx_matrix_data = /bits/ 16
					<0x0 0x3C0 0x0
					0x821 0x3C1 0x1
					0x1042 0x3C2 0x2
					0x1863 0x3C3 0x3
					0x2084 0x3C4 0x4
					0x28A5 0x3C5 0x5
					0x30C6 0x3C6 0x6
					0x38E7 0x3C7 0x7
					0x4107 0x3C8 0x8
					0x4927 0x3C9 0x9
					0x5947 0x3CA 0xa
					0x6167 0x3CB 0xb
					0x6987 0x3CC 0xc
					0x71A7 0x3CD 0xd
					0x79C7 0x3CE 0xe
					0x81E7 0x3CF 0xf
					0x8A07 0x3D0 0x10
					0x8A47 0x3D1 0x11
					0x8A67 0x3D2 0x12
					0x8A87 0x3D3 0x13
					0x8AA7 0x3D4 0x14
					0x8AE7 0x3D5 0x15
					0x8B07 0x3D6 0x16
					0x8B27 0x3D7 0x17
					0x8B67 0x3D8 0x18
					0x8B87 0x3D9 0x19
					0x8BC7 0x3DA 0x1a
					0x8C07 0x3DB 0x1b
					0x8C47 0x3DC 0x1c
					0x8C87 0x3DD 0x1d
					0x8CC7 0x3DE 0x1e
					0x8D07 0x3DF 0x1f
					0x8D67 0x3E0 0x20
					0x8DC7 0x3E1 0x21
					0x8E27 0x3E2 0x22
					0x8EA7 0x3E3 0x23
					0x8F67 0x3E4 0x24
					0x8FE7 0x3E5 0x25
					0x8FE7 0x3E6 0x26
					0x8FE7 0x3E7 0x27
					0x8FE7 0x3E8 0x28>;

		#interrupt-cells = <1>;
		interrupt-map-mask = <0 0 0 7>;
		interrupt-map = <0 0 0 1 &pcie2_intc 1>, /* INT A */
				<0 0 0 2 &pcie2_intc 2>, /* INT B */
				<0 0 0 3 &pcie2_intc 3>, /* INT C */
				<0 0 0 4 &pcie2_intc 4>; /* INT D */
		pcie2_intc: interrupt-controller {
			interrupt-controller;
			#address-cells = <0>;
			#interrupt-cells = <1>;
		};
	};
pcie7: pcie@f4326800 {
		compatible = "cortina-access,mercury-pcie";
		reg = <0x0 0xf4326800 0x0 0x00000800>,
		      <0x0 0xd0000000 0x0 0x00001000>,
		      <0x0 0xd0001000 0x0 0x00002000>,
		      <0x0 0xd0300000 0x0 0x00100000>,
		      <0x0 0xf4330000 0x0 0x00000FFC>;
		reg-names = "glbl_regs", "rc_dbi", "config", "iatu","serdes_phy";

		resets = <&block_rst1 PCI7_RESET>, <&dphy_rst PHY_S7_PCIE_RESET>;
		reset-names = "core_reset", "phy_reset";

		phys = <&s7_pcie_phy>;
		phy-names = "pcie-phy";

		#address-cells = <3>;
		#size-cells = <2>;

		device_type = "pci";
		bus-range = <0x0 0xff>;
		ranges = <0x81000000 0 0          0 0xd0003000 0 0x00010000
			/* downstream I/O */
			/* 0xb0300000 - 0xb03fffff reserved for controller */
			0x82000000 0 0xd0400000 0 0xd0400000 0 0x07e00000>;
			/* non-prefetchable memory */

		id = <7>;
		num-viewport = <1>;
		num-lanes = <1>;
		clocks = <&gate_pcie7_clk>;
		//iommus = <&pcie7_atu>;

		interrupt-parent = <&gic>;
		interrupts = <GIC_SPI IRQ_GLB_PCIE7_GIC0 IRQ_TYPE_LEVEL_HIGH>,
					/* controller interrupt */
					<GIC_SPI IRQ_GLB_PCIE7_GIC1 IRQ_TYPE_LEVEL_HIGH>,
					<GIC_SPI IRQ_GLB_PCIE7_GIC2 IRQ_TYPE_LEVEL_HIGH>,
					<GIC_SPI IRQ_GLB_PCIE7_GIC3 IRQ_TYPE_LEVEL_HIGH>;

		irq-affinity = <1>;  /*RTK wifi. Bound to CPU1. */

		status = "disabled";
		/* Serdes PHY parameters */
		serdes-cfg-verA = "revA v0.4 (2025.01.02)";
		serdes-cfg-dataA = /*S7, GEN1*/
					<0x4 0x2853>,
					<0x20 0x3019>,
					<0x2c 0xaf0d>,
					<0x34 0xe726>,
					<0x38 0x5000>,
					<0x80 0x44ca>,
					<0x84 0x67aa>,
					<0x8c 0x4b46>,
					<0x9c 0x04cb>,
					<0xa8 0x4d45>,
					<0xac 0xb0d1>,
					<0xbc 0xa053>,
					<0x158 0x7110>,
				/*GEN2*/
					<0x220 0x3019>,
					<0x22c 0xaf0d>,
					<0x234 0xe726>,
					<0x238 0x5000>,
					<0x280 0x44ea>,
					<0x284 0xa7aa>,
					<0x28c 0x1b46>,
					<0x29c 0x4cb>,
					<0x2a8 0x4d45>,
					<0x2ac 0xb091>,
					<0x358 0x7110>;

		#interrupt-cells = <1>;
		interrupt-map-mask = <0 0 0 7>;
		interrupt-map = <0 0 0 1 &pcie7_intc 1>, /* INT A */
				<0 0 0 2 &pcie7_intc 2>, /* INT B */
				<0 0 0 3 &pcie7_intc 3>, /* INT C */
				<0 0 0 4 &pcie7_intc 4>; /* INT D */
		pcie7_intc: interrupt-controller {
			interrupt-controller;
			#address-cells = <0>;
			#interrupt-cells = <1>;
		};
	};

	pcie8: pcie@f4327000 {
		compatible = "cortina-access,mercury-pcie";
		reg = <0x0 0xf4327000 0x0 0x00000800>,
		      <0x0 0xd8000000 0x0 0x00001000>,
		      <0x0 0xd8001000 0x0 0x00002000>,
		      <0x0 0xd8300000 0x0 0x00100000>,
		      <0x0 0xf4331000 0x0 0x00000FFC>;
		reg-names = "glbl_regs", "rc_dbi", "config", "iatu","serdes_phy";

		resets = <&block_rst1 PCI8_RESET>, <&dphy_rst PHY_S8_PCIE_RESET>;
		reset-names = "core_reset", "phy_reset";

		phys = <&s8_pcie_phy>;
		phy-names = "pcie-phy";

		#address-cells = <3>;
		#size-cells = <2>;

		device_type = "pci";
		bus-range = <0x0 0xff>;
		ranges = <0x81000000 0 0          0 0xd8003000 0 0x00010000
			/* downstream I/O */
			/* 0xb0300000 - 0xb03fffff reserved for controller */
			0x82000000 0 0xd8400000 0 0xd8400000 0 0x07e00000>;
			/* non-prefetchable memory */
		id = <8>;
		num-viewport = <1>;
		num-lanes = <1>;
		clocks = <&gate_pcie8_clk>;
		//iommus = <&pcie8_atu>;

		interrupt-parent = <&gic>;
		interrupts = <GIC_SPI IRQ_GLB_PCIE8_GIC0 IRQ_TYPE_LEVEL_HIGH>,
					/* controller interrupt */
					<GIC_SPI IRQ_GLB_PCIE8_GIC1 IRQ_TYPE_LEVEL_HIGH>,
					<GIC_SPI IRQ_GLB_PCIE8_GIC2 IRQ_TYPE_LEVEL_HIGH>,
					<GIC_SPI IRQ_GLB_PCIE8_GIC3 IRQ_TYPE_LEVEL_HIGH>;

		irq-affinity = <1>;  /*RTK wifi. Bound to CPU1. */

		status = "disabled";
		/* Serdes PHY parameters */
		serdes-cfg-verA = "revA v0.4 (2025.01.02)";
		serdes-cfg-dataA = /*S8, GEN1*/
					<0x4 0x2853>,
					<0x20 0x3019>,
					<0x2c 0xaf0d>,
					<0x34 0xe726>,
					<0x38 0x5000>,
					<0x80 0x44ca>,
					<0x84 0x67aa>,
					<0x8c 0x4b46>,
					<0x9c 0x04cb>,
					<0xa8 0x4d45>,
					<0xac 0xb0d1>,
					<0xbc 0xa053>,
					<0x158 0x7110>,
				/*GEN2*/
					<0x220 0x3019>,
					<0x22c 0xaf0d>,
					<0x234 0xe726>,
					<0x238 0x5000>,
					<0x280 0x44ea>,
					<0x284 0xa7aa>,
					<0x28c 0x1b46>,
					<0x29c 0x4cb>,
					<0x2a8 0x4d45>,
					<0x2ac 0xb091>,
					<0x358 0x7110>;

		#interrupt-cells = <1>;
		interrupt-map-mask = <0 0 0 7>;
		interrupt-map = <0 0 0 1 &pcie8_intc 1>, /* INT A */
				<0 0 0 2 &pcie8_intc 2>, /* INT B */
				<0 0 0 3 &pcie8_intc 3>, /* INT C */
				<0 0 0 4 &pcie8_intc 4>; /* INT D */
		pcie8_intc: interrupt-controller {
			interrupt-controller;
			#address-cells = <0>;
			#interrupt-cells = <1>;
		};
	};
};
